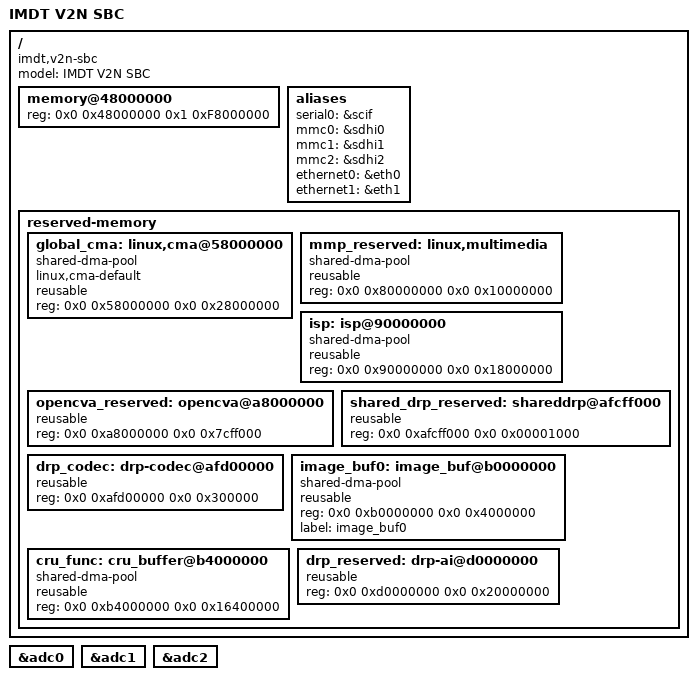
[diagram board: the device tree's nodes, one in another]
/dts-v1/;
#include "r9a09g056.dtsi"
#include <dt-bindings/pinctrl/rzg2l-pinctrl.h>
#include <dt-bindings/gpio/gpio.h>

#include "imdt-v2-sbc.dtsi"
/ {
	model = "IMDT V2N SBC";
	compatible = "imdt,v2n-sbc", "renesas,r9a09g056n44", "renesas,r9a09g056";
	/*Only one memory chip on the V2N */
	memory@48000000 {
		device_type = "memory";
		/* first 128MB is reserved for secure area. */
		reg = <0x0 0x48000000 0x1 0xF8000000>;
	};
	aliases {
		serial0 = &scif;
		mmc0 = &sdhi0;
		mmc1 = &sdhi1;
		mmc2 = &sdhi2;
		ethernet0 = &eth0;
		ethernet1 = &eth1;
	};
	reserved-memory {
		#address-cells = <2>;
		#size-cells = <2>;
		ranges;

	global_cma: linux,cma@58000000 {
			compatible = "shared-dma-pool";
			linux,cma-default;
			reusable;
			reg = <0x0 0x58000000 0x0 0x28000000>;
		};

		mmp_reserved: linux,multimedia {
			compatible = "shared-dma-pool";
			reusable;
			reg = <0x0 0x80000000 0x0 0x10000000>;
		};

		isp: isp@90000000 {
			compatible = "shared-dma-pool";
			reusable;
			reg = <0x0 0x90000000 0x0 0x18000000>;
		};

		opencva_reserved: opencva@a8000000 {
			reusable;
			reg = <0x0 0xa8000000 0x0 0x7cff000>;
		};

		shared_drp_reserved: shareddrp@afcff000 {
			reusable;
			reg = <0x0 0xafcff000 0x0 0x00001000>;
		};

		drp_codec: drp-codec@afd00000 {
			reusable;
			reg = <0x0 0xafd00000 0x0 0x300000>;
		};

		image_buf0: image_buf@b0000000 {
			compatible = "shared-dma-pool";
			reusable;
			reg = <0x0 0xb0000000 0x0 0x4000000>;
			label = "image_buf0";
		};

		cru_func: cru_buffer@b4000000 {
			compatible = "shared-dma-pool";
			reusable;
			reg = <0x0 0xb4000000 0x0 0x16400000>;
		};

		drp_reserved: drp-ai@d0000000 {
			reusable;
			reg = <0x0 0xd0000000 0x0 0x20000000>;
		};
	};

};
&adc0 {
	status = "okay";
};

&adc1 {
	status = "okay";
};

&adc2 {
	status = "okay";
};

